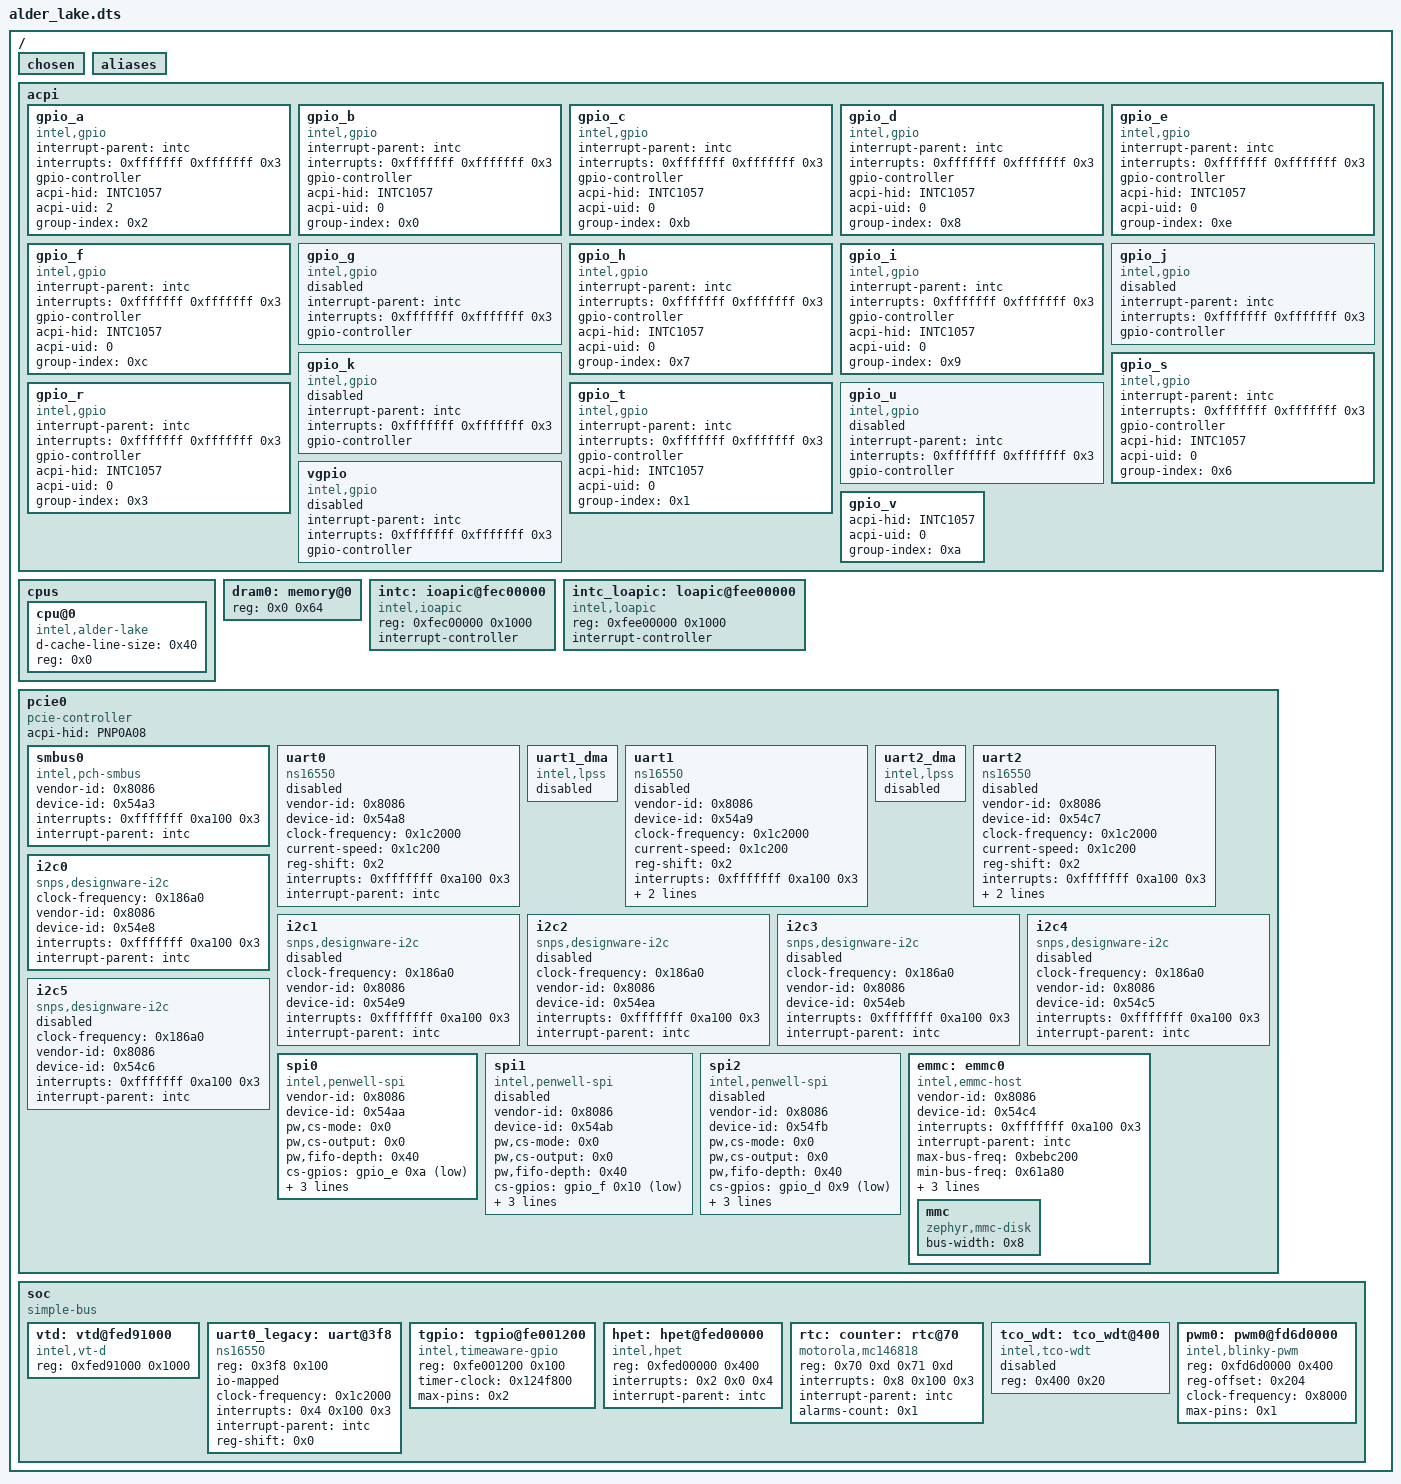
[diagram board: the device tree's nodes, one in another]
/dts-v1/;

/ {
	#address-cells = < 0x1 >;
	#size-cells = < 0x1 >;
	chosen {
	};
	aliases {
	};
	acpi {
		gpio_a: gpio_a {
			compatible = "intel,gpio";
			interrupt-parent = < &intc >;
			interrupts = < 0xfffffff 0xfffffff 0x3 >;
			gpio-controller;
			#gpio-cells = < 0x2 >;
			status = "okay";
			acpi-hid = "INTC1057";
			acpi-uid = "2";
			group-index = < 0x2 >;
		};
		gpio_b: gpio_b {
			compatible = "intel,gpio";
			interrupt-parent = < &intc >;
			interrupts = < 0xfffffff 0xfffffff 0x3 >;
			gpio-controller;
			#gpio-cells = < 0x2 >;
			status = "okay";
			acpi-hid = "INTC1057";
			acpi-uid = "0";
			group-index = < 0x0 >;
		};
		gpio_c: gpio_c {
			compatible = "intel,gpio";
			interrupt-parent = < &intc >;
			interrupts = < 0xfffffff 0xfffffff 0x3 >;
			gpio-controller;
			#gpio-cells = < 0x2 >;
			status = "okay";
			acpi-hid = "INTC1057";
			acpi-uid = "0";
			group-index = < 0xb >;
		};
		gpio_d: gpio_d {
			compatible = "intel,gpio";
			interrupt-parent = < &intc >;
			interrupts = < 0xfffffff 0xfffffff 0x3 >;
			gpio-controller;
			#gpio-cells = < 0x2 >;
			status = "okay";
			acpi-hid = "INTC1057";
			acpi-uid = "0";
			group-index = < 0x8 >;
			phandle = < 0x6 >;
		};
		gpio_e: gpio_e {
			compatible = "intel,gpio";
			interrupt-parent = < &intc >;
			interrupts = < 0xfffffff 0xfffffff 0x3 >;
			gpio-controller;
			#gpio-cells = < 0x2 >;
			status = "okay";
			acpi-hid = "INTC1057";
			acpi-uid = "0";
			group-index = < 0xe >;
			phandle = < 0x4 >;
		};
		gpio_f: gpio_f {
			compatible = "intel,gpio";
			interrupt-parent = < &intc >;
			interrupts = < 0xfffffff 0xfffffff 0x3 >;
			gpio-controller;
			#gpio-cells = < 0x2 >;
			status = "okay";
			acpi-hid = "INTC1057";
			acpi-uid = "0";
			group-index = < 0xc >;
			phandle = < 0x5 >;
		};
		gpio_g: gpio_g {
			compatible = "intel,gpio";
			interrupt-parent = < &intc >;
			interrupts = < 0xfffffff 0xfffffff 0x3 >;
			gpio-controller;
			#gpio-cells = < 0x2 >;
			status = "disabled";
		};
		gpio_h: gpio_h {
			compatible = "intel,gpio";
			interrupt-parent = < &intc >;
			interrupts = < 0xfffffff 0xfffffff 0x3 >;
			gpio-controller;
			#gpio-cells = < 0x2 >;
			status = "okay";
			acpi-hid = "INTC1057";
			acpi-uid = "0";
			group-index = < 0x7 >;
		};
		gpio_i: gpio_i {
			compatible = "intel,gpio";
			interrupt-parent = < &intc >;
			interrupts = < 0xfffffff 0xfffffff 0x3 >;
			gpio-controller;
			#gpio-cells = < 0x2 >;
			status = "okay";
			acpi-hid = "INTC1057";
			acpi-uid = "0";
			group-index = < 0x9 >;
		};
		gpio_j: gpio_j {
			compatible = "intel,gpio";
			interrupt-parent = < &intc >;
			interrupts = < 0xfffffff 0xfffffff 0x3 >;
			gpio-controller;
			#gpio-cells = < 0x2 >;
			status = "disabled";
		};
		gpio_k: gpio_k {
			compatible = "intel,gpio";
			interrupt-parent = < &intc >;
			interrupts = < 0xfffffff 0xfffffff 0x3 >;
			gpio-controller;
			#gpio-cells = < 0x2 >;
			status = "disabled";
		};
		gpio_s: gpio_s {
			compatible = "intel,gpio";
			interrupt-parent = < &intc >;
			interrupts = < 0xfffffff 0xfffffff 0x3 >;
			gpio-controller;
			#gpio-cells = < 0x2 >;
			status = "okay";
			acpi-hid = "INTC1057";
			acpi-uid = "0";
			group-index = < 0x6 >;
		};
		gpio_r: gpio_r {
			compatible = "intel,gpio";
			interrupt-parent = < &intc >;
			interrupts = < 0xfffffff 0xfffffff 0x3 >;
			gpio-controller;
			#gpio-cells = < 0x2 >;
			status = "okay";
			acpi-hid = "INTC1057";
			acpi-uid = "0";
			group-index = < 0x3 >;
		};
		gpio_t: gpio_t {
			compatible = "intel,gpio";
			interrupt-parent = < &intc >;
			interrupts = < 0xfffffff 0xfffffff 0x3 >;
			gpio-controller;
			#gpio-cells = < 0x2 >;
			status = "okay";
			acpi-hid = "INTC1057";
			acpi-uid = "0";
			group-index = < 0x1 >;
		};
		gpio_u: gpio_u {
			compatible = "intel,gpio";
			interrupt-parent = < &intc >;
			interrupts = < 0xfffffff 0xfffffff 0x3 >;
			gpio-controller;
			#gpio-cells = < 0x2 >;
			status = "disabled";
		};
		vgpio: vgpio {
			compatible = "intel,gpio";
			interrupt-parent = < &intc >;
			interrupts = < 0xfffffff 0xfffffff 0x3 >;
			gpio-controller;
			#gpio-cells = < 0x2 >;
			status = "disabled";
		};
		gpio_v: gpio_v {
			acpi-hid = "INTC1057";
			acpi-uid = "0";
			group-index = < 0xa >;
			status = "okay";
		};
	};
	cpus {
		#address-cells = < 0x1 >;
		#size-cells = < 0x0 >;
		cpu@0 {
			device_type = "cpu";
			compatible = "intel,alder-lake";
			d-cache-line-size = < 0x40 >;
			reg = < 0x0 >;
		};
	};
	dram0: memory@0 {
		device_type = "memory";
		reg = < 0x0 0x64 >;
	};
	intc: ioapic@fec00000 {
		compatible = "intel,ioapic";
		#address-cells = < 0x1 >;
		#interrupt-cells = < 0x3 >;
		reg = < 0xfec00000 0x1000 >;
		interrupt-controller;
		phandle = < 0x1 >;
	};
	intc_loapic: loapic@fee00000 {
		compatible = "intel,loapic";
		reg = < 0xfee00000 0x1000 >;
		interrupt-controller;
		#interrupt-cells = < 0x3 >;
		#address-cells = < 0x1 >;
	};
	pcie0: pcie0 {
		#address-cells = < 0x1 >;
		#size-cells = < 0x1 >;
		compatible = "pcie-controller";
		acpi-hid = "PNP0A08";
		ranges;
		smbus0: smbus0 {
			compatible = "intel,pch-smbus";
			#address-cells = < 0x1 >;
			#size-cells = < 0x0 >;
			vendor-id = < 0x8086 >;
			device-id = < 0x54a3 >;
			interrupts = < 0xfffffff 0xa100 0x3 >;
			interrupt-parent = < &intc >;
			status = "okay";
		};
		uart0: uart0 {
			compatible = "ns16550";
			vendor-id = < 0x8086 >;
			device-id = < 0x54a8 >;
			clock-frequency = < 0x1c2000 >;
			current-speed = < 0x1c200 >;
			reg-shift = < 0x2 >;
			interrupts = < 0xfffffff 0xa100 0x3 >;
			interrupt-parent = < &intc >;
			status = "disabled";
		};
		uart1_dma: uart1_dma {
			compatible = "intel,lpss";
			#dma-cells = < 0x1 >;
			status = "disabled";
			phandle = < 0x2 >;
		};
		uart1: uart1 {
			compatible = "ns16550";
			vendor-id = < 0x8086 >;
			device-id = < 0x54a9 >;
			clock-frequency = < 0x1c2000 >;
			current-speed = < 0x1c200 >;
			reg-shift = < 0x2 >;
			interrupts = < 0xfffffff 0xa100 0x3 >;
			interrupt-parent = < &intc >;
			dmas = < &uart1_dma 0x0 >, < &uart1_dma 0x1 >;
			dma-names = "tx", "rx";
			status = "disabled";
		};
		uart2_dma: uart2_dma {
			compatible = "intel,lpss";
			#dma-cells = < 0x1 >;
			status = "disabled";
			phandle = < 0x3 >;
		};
		uart2: uart2 {
			compatible = "ns16550";
			vendor-id = < 0x8086 >;
			device-id = < 0x54c7 >;
			clock-frequency = < 0x1c2000 >;
			current-speed = < 0x1c200 >;
			reg-shift = < 0x2 >;
			interrupts = < 0xfffffff 0xa100 0x3 >;
			interrupt-parent = < &intc >;
			dmas = < &uart2_dma 0x0 >, < &uart2_dma 0x1 >;
			dma-names = "tx", "rx";
			status = "disabled";
		};
		i2c0: i2c0 {
			compatible = "snps,designware-i2c";
			clock-frequency = < 0x186a0 >;
			#address-cells = < 0x1 >;
			#size-cells = < 0x0 >;
			vendor-id = < 0x8086 >;
			device-id = < 0x54e8 >;
			interrupts = < 0xfffffff 0xa100 0x3 >;
			interrupt-parent = < &intc >;
			status = "okay";
		};
		i2c1: i2c1 {
			compatible = "snps,designware-i2c";
			clock-frequency = < 0x186a0 >;
			#address-cells = < 0x1 >;
			#size-cells = < 0x0 >;
			vendor-id = < 0x8086 >;
			device-id = < 0x54e9 >;
			interrupts = < 0xfffffff 0xa100 0x3 >;
			interrupt-parent = < &intc >;
			status = "disabled";
		};
		i2c2: i2c2 {
			compatible = "snps,designware-i2c";
			clock-frequency = < 0x186a0 >;
			#address-cells = < 0x1 >;
			#size-cells = < 0x0 >;
			vendor-id = < 0x8086 >;
			device-id = < 0x54ea >;
			interrupts = < 0xfffffff 0xa100 0x3 >;
			interrupt-parent = < &intc >;
			status = "disabled";
		};
		i2c3: i2c3 {
			compatible = "snps,designware-i2c";
			clock-frequency = < 0x186a0 >;
			#address-cells = < 0x1 >;
			#size-cells = < 0x0 >;
			vendor-id = < 0x8086 >;
			device-id = < 0x54eb >;
			interrupts = < 0xfffffff 0xa100 0x3 >;
			interrupt-parent = < &intc >;
			status = "disabled";
		};
		i2c4: i2c4 {
			compatible = "snps,designware-i2c";
			clock-frequency = < 0x186a0 >;
			#address-cells = < 0x1 >;
			#size-cells = < 0x0 >;
			vendor-id = < 0x8086 >;
			device-id = < 0x54c5 >;
			interrupts = < 0xfffffff 0xa100 0x3 >;
			interrupt-parent = < &intc >;
			status = "disabled";
		};
		i2c5: i2c5 {
			compatible = "snps,designware-i2c";
			clock-frequency = < 0x186a0 >;
			#address-cells = < 0x1 >;
			#size-cells = < 0x0 >;
			vendor-id = < 0x8086 >;
			device-id = < 0x54c6 >;
			interrupts = < 0xfffffff 0xa100 0x3 >;
			interrupt-parent = < &intc >;
			status = "disabled";
		};
		spi0: spi0 {
			compatible = "intel,penwell-spi";
			vendor-id = < 0x8086 >;
			device-id = < 0x54aa >;
			#address-cells = < 0x1 >;
			#size-cells = < 0x0 >;
			pw,cs-mode = < 0x0 >;
			pw,cs-output = < 0x0 >;
			pw,fifo-depth = < 0x40 >;
			cs-gpios = < &gpio_e 0xa 0x1 >;
			clock-frequency = < 0x5f5e100 >;
			interrupts = < 0xfffffff 0xa100 0x3 >;
			interrupt-parent = < &intc >;
			status = "okay";
		};
		spi1: spi1 {
			compatible = "intel,penwell-spi";
			vendor-id = < 0x8086 >;
			device-id = < 0x54ab >;
			#address-cells = < 0x1 >;
			#size-cells = < 0x0 >;
			pw,cs-mode = < 0x0 >;
			pw,cs-output = < 0x0 >;
			pw,fifo-depth = < 0x40 >;
			cs-gpios = < &gpio_f 0x10 0x1 >;
			clock-frequency = < 0x5f5e100 >;
			interrupts = < 0xfffffff 0xa100 0x3 >;
			interrupt-parent = < &intc >;
			status = "disabled";
		};
		spi2: spi2 {
			compatible = "intel,penwell-spi";
			vendor-id = < 0x8086 >;
			device-id = < 0x54fb >;
			#address-cells = < 0x1 >;
			#size-cells = < 0x0 >;
			pw,cs-mode = < 0x0 >;
			pw,cs-output = < 0x0 >;
			pw,fifo-depth = < 0x40 >;
			cs-gpios = < &gpio_d 0x9 0x1 >;
			clock-frequency = < 0x5f5e100 >;
			interrupts = < 0xfffffff 0xa100 0x3 >;
			interrupt-parent = < &intc >;
			status = "disabled";
		};
		emmc: emmc0 {
			compatible = "intel,emmc-host";
			vendor-id = < 0x8086 >;
			device-id = < 0x54c4 >;
			interrupts = < 0xfffffff 0xa100 0x3 >;
			interrupt-parent = < &intc >;
			max-bus-freq = < 0xbebc200 >;
			min-bus-freq = < 0x61a80 >;
			power-delay-ms = < 0x1f4 >;
			mmc-hs400-1_8v;
			mmc-hs200-1_8v;
			status = "okay";
			mmc {
				compatible = "zephyr,mmc-disk";
				bus-width = < 0x8 >;
				status = "okay";
			};
		};
	};
	soc {
		#address-cells = < 0x1 >;
		#size-cells = < 0x1 >;
		compatible = "simple-bus";
		ranges;
		vtd: vtd@fed91000 {
			compatible = "intel,vt-d";
			reg = < 0xfed91000 0x1000 >;
			status = "okay";
		};
		uart0_legacy: uart@3f8 {
			compatible = "ns16550";
			reg = < 0x3f8 0x100 >;
			io-mapped;
			clock-frequency = < 0x1c2000 >;
			interrupts = < 0x4 0x100 0x3 >;
			interrupt-parent = < &intc >;
			reg-shift = < 0x0 >;
			status = "okay";
		};
		tgpio: tgpio@fe001200 {
			compatible = "intel,timeaware-gpio";
			reg = < 0xfe001200 0x100 >;
			timer-clock = < 0x124f800 >;
			max-pins = < 0x2 >;
			status = "okay";
		};
		hpet: hpet@fed00000 {
			compatible = "intel,hpet";
			reg = < 0xfed00000 0x400 >;
			interrupts = < 0x2 0x0 0x4 >;
			interrupt-parent = < &intc >;
			status = "okay";
		};
		rtc: counter: rtc@70 {
			compatible = "motorola,mc146818";
			reg = < 0x70 0xd 0x71 0xd >;
			interrupts = < 0x8 0x100 0x3 >;
			interrupt-parent = < &intc >;
			alarms-count = < 0x1 >;
			status = "okay";
		};
		tco_wdt: tco_wdt@400 {
			compatible = "intel,tco-wdt";
			reg = < 0x400 0x20 >;
			status = "disabled";
		};
		pwm0: pwm0@fd6d0000 {
			compatible = "intel,blinky-pwm";
			reg = < 0xfd6d0000 0x400 >;
			reg-offset = < 0x204 >;
			clock-frequency = < 0x8000 >;
			max-pins = < 0x1 >;
			#pwm-cells = < 0x2 >;
			status = "okay";
		};
	};
};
